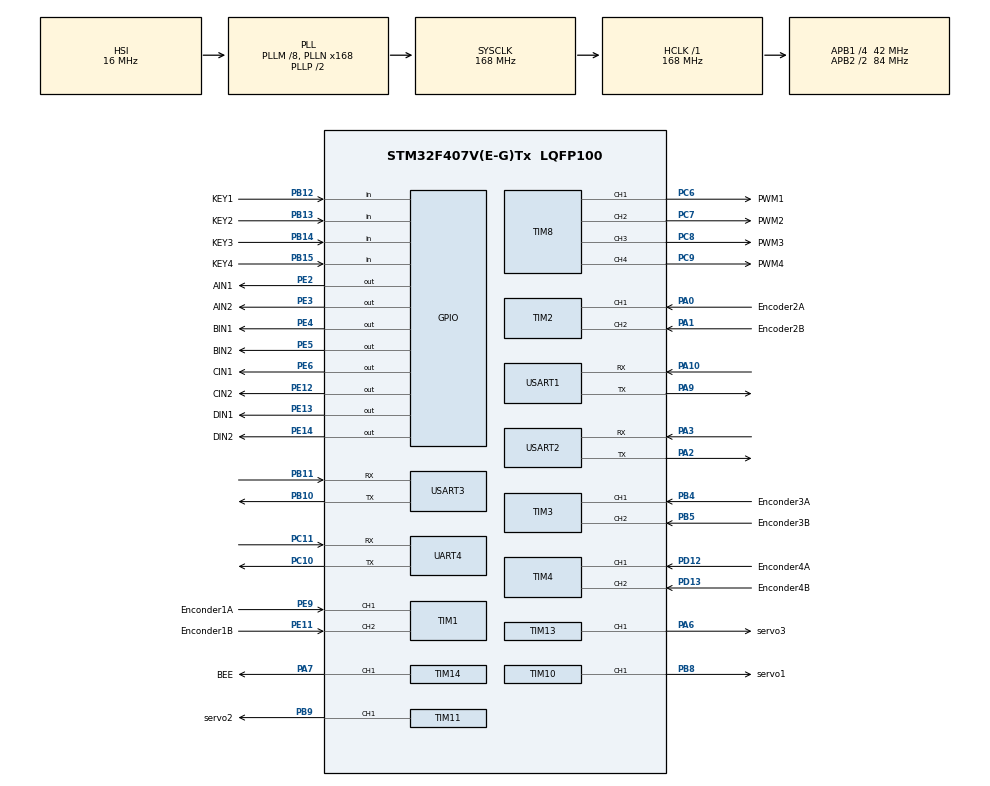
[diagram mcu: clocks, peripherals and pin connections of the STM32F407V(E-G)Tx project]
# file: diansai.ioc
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Dma.Request0=USART2_RX
Dma.Request1=USART2_TX
Dma.Request2=USART1_RX
Dma.Request3=USART1_TX
Dma.USART1_RX.2.Direction=DMA_PERIPH_TO_MEMORY
Dma.USART1_RX.2.FIFOMode=DMA_FIFOMODE_DISABLE
Dma.USART1_RX.2.Instance=DMA2_Stream2
Dma.USART1_RX.2.MemDataAlignment=DMA_MDATAALIGN_BYTE
Dma.USART1_RX.2.MemInc=DMA_MINC_ENABLE
Dma.USART1_RX.2.Mode=DMA_NORMAL
Dma.USART1_RX.2.PeriphDataAlignment=DMA_PDATAALIGN_BYTE
Dma.USART1_RX.2.PeriphInc=DMA_PINC_DISABLE
Dma.USART1_RX.2.Priority=DMA_PRIORITY_LOW
Dma.USART1_TX.3.Direction=DMA_MEMORY_TO_PERIPH
Dma.USART1_TX.3.FIFOMode=DMA_FIFOMODE_DISABLE
Dma.USART1_TX.3.Instance=DMA2_Stream7
Dma.USART1_TX.3.MemDataAlignment=DMA_MDATAALIGN_BYTE
Dma.USART1_TX.3.MemInc=DMA_MINC_ENABLE
Dma.USART1_TX.3.Mode=DMA_NORMAL
Dma.USART1_TX.3.PeriphDataAlignment=DMA_PDATAALIGN_BYTE
Dma.USART1_TX.3.PeriphInc=DMA_PINC_DISABLE
Dma.USART1_TX.3.Priority=DMA_PRIORITY_LOW
Dma.USART2_RX.0.Direction=DMA_PERIPH_TO_MEMORY
Dma.USART2_RX.0.FIFOMode=DMA_FIFOMODE_DISABLE
Dma.USART2_RX.0.Instance=DMA1_Stream5
Dma.USART2_RX.0.MemDataAlignment=DMA_MDATAALIGN_BYTE
Dma.USART2_RX.0.MemInc=DMA_MINC_ENABLE
Dma.USART2_RX.0.Mode=DMA_NORMAL
Dma.USART2_RX.0.PeriphDataAlignment=DMA_PDATAALIGN_BYTE
Dma.USART2_RX.0.PeriphInc=DMA_PINC_DISABLE
Dma.USART2_RX.0.Priority=DMA_PRIORITY_LOW
Dma.USART2_TX.1.Direction=DMA_MEMORY_TO_PERIPH
Dma.USART2_TX.1.FIFOMode=DMA_FIFOMODE_DISABLE
Dma.USART2_TX.1.Instance=DMA1_Stream6
Dma.USART2_TX.1.MemDataAlignment=DMA_MDATAALIGN_BYTE
Dma.USART2_TX.1.MemInc=DMA_MINC_ENABLE
Dma.USART2_TX.1.Mode=DMA_NORMAL
Dma.USART2_TX.1.PeriphDataAlignment=DMA_PDATAALIGN_BYTE
Dma.USART2_TX.1.PeriphInc=DMA_PINC_DISABLE
Dma.USART2_TX.1.Priority=DMA_PRIORITY_LOW
Mcu.Family=STM32F4
Mcu.Name=STM32F407V(E-G)Tx
Mcu.Package=LQFP100
NVIC.DMA1_Stream5_IRQn=true\:0\:0\:false\:false\:true\:false\:true\:true
NVIC.DMA1_Stream6_IRQn=true\:0\:0\:false\:false\:true\:false\:true\:true
NVIC.DMA2_Stream2_IRQn=true\:0\:0\:false\:false\:true\:false\:true\:true
NVIC.DMA2_Stream7_IRQn=true\:0\:0\:false\:false\:true\:false\:true\:true
NVIC.PriorityGroup=NVIC_PRIORITYGROUP_4
NVIC.TIM6_DAC_IRQn=true\:0\:0\:false\:false\:true\:true\:true\:true
NVIC.TIM7_IRQn=true\:0\:0\:false\:false\:true\:true\:true\:true
NVIC.USART2_IRQn=true\:0\:0\:false\:false\:true\:true\:true\:true
PA0-WKUP.GPIO_Label=Encoder2A
PA0-WKUP.Signal=S_TIM2_CH1_ETR
PA1.GPIO_Label=Encoder2B
PA1.Signal=S_TIM2_CH2
PA10.Mode=Asynchronous
PA10.Signal=USART1_RX
PA2.Mode=Asynchronous
PA2.Signal=USART2_TX
PA3.Mode=Asynchronous
PA3.Signal=USART2_RX
PA6.GPIO_Label=servo3
PA6.Signal=S_TIM13_CH1
PA7.GPIO_Label=BEE
PA7.Signal=S_TIM14_CH1
PA9.Mode=Asynchronous
PA9.Signal=USART1_TX
PB10.Mode=Asynchronous
PB10.Signal=USART3_TX
PB11.Mode=Asynchronous
PB11.Signal=USART3_RX
PB12.GPIO_Label=KEY1
PB12.Signal=GPIO_Input
PB13.GPIO_Label=KEY2
PB13.Signal=GPIO_Input
PB14.GPIO_Label=KEY3
PB14.Signal=GPIO_Input
PB15.GPIO_Label=KEY4
PB15.Signal=GPIO_Input
PB4.GPIO_Label=Enconder3A
PB4.Signal=S_TIM3_CH1
PB5.GPIO_Label=Enconder3B
PB5.Signal=S_TIM3_CH2
PB8.GPIO_Label=servo1
PB8.Signal=S_TIM10_CH1
PB9.GPIO_Label=servo2
PB9.Signal=S_TIM11_CH1
PC10.Mode=Asynchronous
PC10.Signal=UART4_TX
PC11.Mode=Asynchronous
PC11.Signal=UART4_RX
PC6.GPIO_Label=PWM1
PC6.Signal=S_TIM8_CH1
PC7.GPIO_Label=PWM2
PC7.Signal=S_TIM8_CH2
PC8.GPIO_Label=PWM3
PC8.Signal=S_TIM8_CH3
PC9.GPIO_Label=PWM4
PC9.Signal=S_TIM8_CH4
PD12.GPIO_Label=Enconder4A
PD12.Signal=S_TIM4_CH1
PD13.GPIO_Label=Enconder4B
PD13.Signal=S_TIM4_CH2
PE11.GPIO_Label=Enconder1B
PE11.Signal=S_TIM1_CH2
PE12.GPIO_Label=CIN2
PE12.Signal=GPIO_Output
PE13.GPIO_Label=DIN1
PE13.Signal=GPIO_Output
PE14.GPIO_Label=DIN2
PE14.Signal=GPIO_Output
PE2.GPIO_Label=AIN1
PE2.GPIO_PuPd=GPIO_PULLUP
PE2.Signal=GPIO_Output
PE3.GPIO_Label=AIN2
PE3.Signal=GPIO_Output
PE4.GPIO_Label=BIN1
PE4.Signal=GPIO_Output
PE5.GPIO_Label=BIN2
PE5.Signal=GPIO_Output
PE6.GPIO_Label=CIN1
PE6.Signal=GPIO_Output
PE9.GPIO_Label=Enconder1A
PE9.Signal=S_TIM1_CH1
ProjectManager.HeapSize=0x200
ProjectManager.StackSize=0x400
ProjectManager.TargetToolchain=MDK-ARM V5.32
RCC.48MHZClocksFreq_Value=84000000
RCC.AHBFreq_Value=168000000
RCC.APB1CLKDivider=RCC_HCLK_DIV4
RCC.APB1Freq_Value=42000000
RCC.APB1TimFreq_Value=84000000
RCC.APB2CLKDivider=RCC_HCLK_DIV2
RCC.APB2Freq_Value=84000000
RCC.APB2TimFreq_Value=168000000
RCC.CortexFreq_Value=168000000
RCC.HCLKFreq_Value=168000000
RCC.HSE_VALUE=25000000
RCC.HSI_VALUE=16000000
RCC.LSE_VALUE=32768
RCC.PLLM=8
RCC.PLLN=168
RCC.SYSCLKFreq_VALUE=168000000
RCC.SYSCLKSource=RCC_SYSCLKSOURCE_PLLCLK
RCC.VCOOutputFreq_Value=336000000
SH.S_TIM10_CH1.0=TIM10_CH1,PWM Generation1 CH1
SH.S_TIM11_CH1.0=TIM11_CH1,PWM Generation1 CH1
SH.S_TIM13_CH1.0=TIM13_CH1,PWM Generation1 CH1
SH.S_TIM14_CH1.0=TIM14_CH1,PWM Generation1 CH1
SH.S_TIM1_CH1.0=TIM1_CH1,Encoder_Interface
SH.S_TIM1_CH2.0=TIM1_CH2,Encoder_Interface
SH.S_TIM2_CH1_ETR.0=TIM2_CH1,Encoder_Interface
SH.S_TIM2_CH2.0=TIM2_CH2,Encoder_Interface
SH.S_TIM3_CH1.0=TIM3_CH1,Encoder_Interface
SH.S_TIM3_CH2.0=TIM3_CH2,Encoder_Interface
SH.S_TIM4_CH1.0=TIM4_CH1,Encoder_Interface
SH.S_TIM4_CH2.0=TIM4_CH2,Encoder_Interface
SH.S_TIM8_CH1.0=TIM8_CH1,PWM Generation1 CH1
SH.S_TIM8_CH2.0=TIM8_CH2,Output Compare2 CH2
SH.S_TIM8_CH3.0=TIM8_CH3,Output Compare3 CH3
SH.S_TIM8_CH4.0=TIM8_CH4,Output Compare4 CH4
TIM10.Channel=TIM_CHANNEL_1
TIM10.Period=20000-1
TIM10.Prescaler=168-1
TIM11.Channel=TIM_CHANNEL_1
TIM11.Period=20000-1
TIM11.Prescaler=168-1
TIM13.Channel=TIM_CHANNEL_1
TIM13.Period=20000-1
TIM13.Prescaler=168-1
TIM14.Channel=TIM_CHANNEL_1
TIM6.Period=20000-1
TIM6.Prescaler=168-1
TIM7.Period=10000-1
TIM7.Prescaler=168-1
TIM8.Channel-Output\ Compare2\ CH2=TIM_CHANNEL_2
TIM8.Channel-Output\ Compare3\ CH3=TIM_CHANNEL_3
TIM8.Channel-Output\ Compare4\ CH4=TIM_CHANNEL_4
TIM8.Channel-PWM\ Generation1\ CH1=TIM_CHANNEL_1
UART4.VirtualMode=Asynchronous
USART1.VirtualMode=VM_ASYNC
USART2.VirtualMode=VM_ASYNC
USART3.VirtualMode=VM_ASYNC
VP_TIM10_VS_ClockSourceINT.Mode=Enable_Timer
VP_TIM11_VS_ClockSourceINT.Mode=Enable_Timer
VP_TIM13_VS_ClockSourceINT.Mode=Enable_Timer
VP_TIM14_VS_ClockSourceINT.Mode=Enable_Timer
VP_TIM6_VS_ClockSourceINT.Mode=Enable_Timer
VP_TIM7_VS_ClockSourceINT.Mode=Enable_Timer
VP_TIM8_VS_ClockSourceINT.Mode=Internal
board=custom

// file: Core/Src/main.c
/* USER CODE BEGIN Header */
/**
  ******************************************************************************
  * @file           : main.c
  * @brief          : Main program body
  ******************************************************************************
  * @attention
  *
  * Copyright (c) 2025 STMicroelectronics.
  * All rights reserved.
  *
  * This software is licensed under terms that can be found in the LICENSE file
  * in the root directory of this software component.
  * If no LICENSE file comes with this software, it is provided AS-IS.
  *
  ******************************************************************************
  */
/* USER CODE END Header */
#include "main.h"
#include "dma.h"
#include "tim.h"
#include "usart.h"
#include "gpio.h"

/* USER CODE BEGIN Includes */
#include "headfile.h"
/* USER CODE END Includes */

/* USER CODE BEGIN PV */
uint16_t servo_PWM=500;
int test1,test2;
_Bool trans_flag=0;
_Bool servo1_flag=0;
/* USER CODE END PV */

void SystemClock_Config(void);

int main(void)
{

  /* MCU Configuration--------------------------------------------------------*/

  /* Reset of all peripherals, Initializes the Flash interface and the Systick. */
  HAL_Init();

  /* Configure the system clock */
  SystemClock_Config();

  /* Initialize all configured peripherals */
  MX_GPIO_Init();
  MX_DMA_Init();
  MX_TIM1_Init();
  MX_TIM2_Init();
  MX_TIM3_Init();
  MX_TIM4_Init();
  MX_TIM8_Init();
  MX_TIM10_Init();
  MX_TIM11_Init();
  MX_TIM13_Init();
  MX_USART1_UART_Init();
  MX_USART2_UART_Init();
  MX_USART3_UART_Init();
  MX_UART4_Init();
  MX_TIM14_Init();
  MX_TIM7_Init();
  MX_TIM6_Init();
  /* USER CODE BEGIN 2 */
	All_init();

  /* USER CODE END 2 */

  /* Infinite loop */
  /* USER CODE BEGIN WHILE */
  while (1)
  {

	 /*AB*/
	 Fill_XLine(cal_mid(point_data.A1[0],point_data.A2[0]), cal_mid(point_data.A1[1],point_data.A2[1]),cal_mid( point_data.B1[0],point_data.B2[0]), cal_mid(point_data.B1[1],point_data.B2[1]), AB_line);
   /*BC*/
   Fill_YLine(cal_mid(point_data.B1[0],point_data.B2[0]), cal_mid(point_data.B1[1],point_data.B2[1]),cal_mid(point_data.C1[0],point_data.C2[0]), cal_mid(point_data.C1[1],point_data.C2[1]), BC_line);
  /*CD*/

		//Fill_XLine(cal_mid(point_data.C1[0],point_data.C2[0]), cal_mid(point_data.C1[1],point_data.C2[1]),cal_mid(point_data.D1[0],point_data.D2[0]), cal_mid(point_data.D1[1],point_data.D2[1]), CD_line);
	/*DC*/
	 Fill_XLine(cal_mid(point_data.D1[0],point_data.D2[0]), cal_mid(point_data.D1[1],point_data.D2[1]),cal_mid(point_data.C1[0],point_data.C2[0]), cal_mid(point_data.C1[1],point_data.C2[1]), CD_line);

  /*AD*/
   Fill_YLine(cal_mid(point_data.A1[0],point_data.A2[0]), cal_mid(point_data.A1[1],point_data.A2[1]), cal_mid(point_data.D1[0],point_data.D2[0]), cal_mid(point_data.D1[1],point_data.D2[1]), AD_line);

  //LCD_ShowIntNum(0,0,point_data.light[0],3,BLACK,WHITE,16);
  //LCD_ShowIntNum(0,20,point_data.light[1],3,BLACK,WHITE,16);

 //LCD_ShowIntNum(50,0,point_data.A1[0],3,BLACK,WHITE,16);
  //LCD_ShowIntNum(50,20,point_data.A1[1],3,BLACK,WHITE,16);

 // LCD_ShowIntNum(100,0,point_data.mid[0],3,BLACK,WHITE,16);
  //LCD_ShowIntNum(100,20,point_data.mid[1],3,BLACK,WHITE,16);

  //LCD_ShowIntNum(X_1,Y_1,12,2,BLACK,WHITE,16);
  //LCD_ShowIntNum(X_3,Y_1,3,1,BLACK,WHITE,16);
  //LCD_ShowIntNum(X_1,Y_2,123,3,BLACK,WHITE,16);
   LCD_show();
	 key_function();

    /* USER CODE END WHILE */

  }
}

void SystemClock_Config(void)
{
  RCC_OscInitTypeDef RCC_OscInitStruct = {0};
  RCC_ClkInitTypeDef RCC_ClkInitStruct = {0};

  /** Configure the main internal regulator output voltage
  */
  __HAL_RCC_PWR_CLK_ENABLE();
  __HAL_PWR_VOLTAGESCALING_CONFIG(PWR_REGULATOR_VOLTAGE_SCALE1);

  /** Initializes the RCC Oscillators according to the specified parameters
  * in the RCC_OscInitTypeDef structure.
  */
  RCC_OscInitStruct.OscillatorType = RCC_OSCILLATORTYPE_HSI;
  RCC_OscInitStruct.HSIState = RCC_HSI_ON;
  RCC_OscInitStruct.HSICalibrationValue = RCC_HSICALIBRATION_DEFAULT;
  RCC_OscInitStruct.PLL.PLLState = RCC_PLL_ON;
  RCC_OscInitStruct.PLL.PLLSource = RCC_PLLSOURCE_HSI;
  RCC_OscInitStruct.PLL.PLLM = 8;
  RCC_OscInitStruct.PLL.PLLN = 168;
  RCC_OscInitStruct.PLL.PLLP = RCC_PLLP_DIV2;
  RCC_OscInitStruct.PLL.PLLQ = 4;
  if (HAL_RCC_OscConfig(&RCC_OscInitStruct) != HAL_OK)
  {
    Error_Handler();
  }

  /** Initializes the CPU, AHB and APB buses clocks
  */
  RCC_ClkInitStruct.ClockType = RCC_CLOCKTYPE_HCLK|RCC_CLOCKTYPE_SYSCLK
                              |RCC_CLOCKTYPE_PCLK1|RCC_CLOCKTYPE_PCLK2;
  RCC_ClkInitStruct.SYSCLKSource = RCC_SYSCLKSOURCE_PLLCLK;
  RCC_ClkInitStruct.AHBCLKDivider = RCC_SYSCLK_DIV1;
  RCC_ClkInitStruct.APB1CLKDivider = RCC_HCLK_DIV4;
  RCC_ClkInitStruct.APB2CLKDivider = RCC_HCLK_DIV2;

  if (HAL_RCC_ClockConfig(&RCC_ClkInitStruct, FLASH_LATENCY_5) != HAL_OK)
  {
    Error_Handler();
  }
}

void Error_Handler(void)
{
  __disable_irq();
  while (1)
  {
  }
}
